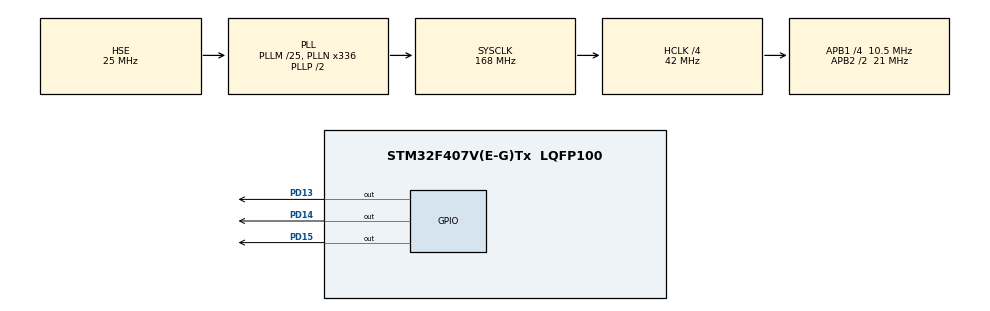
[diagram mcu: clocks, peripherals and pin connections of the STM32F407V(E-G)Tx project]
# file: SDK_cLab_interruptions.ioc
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Mcu.Family=STM32F4
RCC.PLLSourceVirtual=RCC_PLLSOURCE_HSE
PH0-OSC_IN.Signal=RCC_OSC_IN
RCC.CortexFreq_Value=42000000
NVIC.TIM6_DAC_IRQn=true\:0\:0\:false\:false\:true\:true\:true
PD15.GPIO_Speed=GPIO_SPEED_FREQ_HIGH
VP_IWDG_VS_IWDG.Mode=IWDG_Activate
TIM6.Prescaler=42000 - 1
VP_TIM6_VS_ClockSourceINT.Mode=Enable_Timer
RCC.APB1CLKDivider=RCC_HCLK_DIV4
RCC.SYSCLKSource=RCC_SYSCLKSOURCE_PLLCLK
ProjectManager.StackSize=0x400
VP_TIM7_VS_ClockSourceINT.Mode=Enable_Timer
PA13.Signal=SYS_JTMS-SWDIO
PD13.Signal=GPIO_Output
PD14.GPIO_Speed=GPIO_SPEED_FREQ_HIGH
ProjectManager.TargetToolchain=STM32CubeIDE
RCC.HCLKFreq_Value=42000000
RCC.APB2TimFreq_Value=42000000
TIM7.Period=150-1
RCC.LSE_VALUE=32768
RCC.AHBFreq_Value=42000000
PH0-OSC_IN.Mode=HSE-External-Oscillator
RCC.HSE_VALUE=25000000
PB3.Mode=JTAG_5_pins
TIM7.Prescaler=42000-1
board=custom
PD13.GPIO_Speed=GPIO_SPEED_FREQ_HIGH
RCC.VCOOutputFreq_Value=336000000
PA15.Mode=JTAG_5_pins
RCC.APB2Freq_Value=21000000
PB4.Mode=JTAG_5_pins
PA14.Mode=JTAG_5_pins
TIM6.TIM_MasterOutputTrigger=TIM_TRGO_ENABLE
PH1-OSC_OUT.Signal=RCC_OSC_OUT
RCC.AHBCLKDivider=RCC_SYSCLK_DIV4
TIM6.Period=150-1
PA13.Mode=JTAG_5_pins
Mcu.Name=STM32F407V(E-G)Tx
TIM7.TIM_MasterOutputTrigger=TIM_TRGO_ENABLE
PD14.Signal=GPIO_Output
PH1-OSC_OUT.Mode=HSE-External-Oscillator
RCC.48MHZClocksFreq_Value=84000000
PB3.Signal=SYS_JTDO-SWO
RCC.SYSCLKFreq_VALUE=168000000
Mcu.Package=LQFP100
PA14.Signal=SYS_JTCK-SWCLK
PA15.Signal=SYS_JTDI
ProjectManager.HeapSize=0x200
RCC.HSI_VALUE=16000000
NVIC.PriorityGroup=NVIC_PRIORITYGROUP_4
RCC.APB2CLKDivider=RCC_HCLK_DIV2
RCC.PLLM=25
RCC.PLLN=336
IWDG.Prescaler=IWDG_PRESCALER_64
RCC.APB1TimFreq_Value=21000000
RCC.APB1Freq_Value=10500000
PD15.Signal=GPIO_Output
NVIC.TIM7_IRQn=true\:0\:0\:false\:false\:true\:true\:true
PB4.Signal=SYS_JTRST

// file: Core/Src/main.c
/* USER CODE BEGIN Header */
/**
  ******************************************************************************
  * @file           : main.c
  * @brief          : Main program body
  ******************************************************************************
  * @attention
  *
  * <h2><center>&copy; Copyright (c) 2020 STMicroelectronics.
  * All rights reserved.</center></h2>
  *
  * This software component is licensed by ST under BSD 3-Clause license,
  * the "License"; You may not use this file except in compliance with the
  * License. You may obtain a copy of the License at:
  *                        opensource.org/licenses/BSD-3-Clause
  *
  ******************************************************************************
  */
/* USER CODE END Header */
#include "main.h"
#include "iwdg.h"
#include "tim.h"
#include "gpio.h"

/* USER CODE BEGIN Includes */
#include "trace.h"
/* USER CODE END Includes */

/* USER CODE BEGIN PV */
static const int basic_delay = 500;
static const int delay_gain = 15;

static int delay = basic_delay;

static const int frames_count = 12;
static const int leds_count = 8;

static const uint8_t frames[ 12 ][ 8 ] = {
		{ 0, 0, 0, 0, 0, 0, 1, 1 },
		{ 0, 0, 0, 0, 0, 1, 1, 0 },
		{ 0, 0, 0, 0, 1, 1, 0, 0 },
		{ 0, 0, 0, 1, 1, 0, 0, 0 },
		{ 0, 0, 1, 1, 0, 0, 0, 0 },
		{ 0, 1, 1, 0, 0, 0, 0, 0 },
		{ 1, 1, 0, 0, 0, 0, 0, 0 },
		{ 0, 1, 1, 0, 0, 0, 0, 0 },
		{ 0, 0, 1, 1, 0, 0, 0, 0 },
		{ 0, 0, 0, 1, 1, 0, 0, 0 },
		{ 0, 0, 0, 0, 1, 1, 0, 0 },
		{ 0, 0, 0, 0, 0, 1, 1, 0 }
};

static const uint8_t leds_id[] = {
		[ 0 ] = P0,
		[ 1 ] = P1,
		[ 2 ] = P2,
		[ 3 ] = P3,
		[ 4 ] = P4,
		[ 5 ] = P5,
		[ 6 ] = P6,
		[ 7 ] = P7
};
/* USER CODE END PV */

void SystemClock_Config(void);

int main(void)
{

  /* MCU Configuration--------------------------------------------------------*/

  /* Reset of all peripherals, Initializes the Flash interface and the Systick. */
  HAL_Init();

  /* Configure the system clock */
  SystemClock_Config();

  /* Initialize all configured peripherals */
  MX_GPIO_Init();
  MX_IWDG_Init();
  MX_TIM6_Init();
  MX_TIM7_Init();
  /* USER CODE BEGIN 2 */

  HAL_TIM_Base_Start_IT( &htim6 );

  /* Do not remove this code below */
  MX_TRACE_Init();
  SDK_TRACE_Start();
  /* Do not remove this code from above */

  SDK_TRACE_Timestamp(PRINT, 1);
  SDK_TRACE_Print("%s","Interruption Animation test");
  SDK_TRACE_Timestamp(PRINT, 0);
  /* Place your code from here */

  for ( int i = 0; i < frames_count; ++i ) {
	  for ( int led_counter = 0; led_counter < leds_count; ++led_counter )
		  SDK_TRACE_Timestamp( leds_id[ led_counter ], frames[ i ][ led_counter ] );
	  HAL_Delay( delay );
  }

  SDK_TRACE_Timestamp(PRINT, 1);
  SDK_TRACE_Print("%s","Test passed");
  SDK_TRACE_Timestamp(PRINT, 0);

  /* Place your code before here */
  /* Do not remove this code below */
  SDK_TRACE_Stop();
  /* Do not remove this code from above */

  /* USER CODE END 2 */

  /* Infinite loop */
  while (1)
  {

  }
}

void SystemClock_Config(void)
{
  RCC_OscInitTypeDef RCC_OscInitStruct = {0};
  RCC_ClkInitTypeDef RCC_ClkInitStruct = {0};

  /** Configure the main internal regulator output voltage
  */
  __HAL_RCC_PWR_CLK_ENABLE();
  __HAL_PWR_VOLTAGESCALING_CONFIG(PWR_REGULATOR_VOLTAGE_SCALE1);
  /** Initializes the RCC Oscillators according to the specified parameters
  * in the RCC_OscInitTypeDef structure.
  */
  RCC_OscInitStruct.OscillatorType = RCC_OSCILLATORTYPE_LSI|RCC_OSCILLATORTYPE_HSE;
  RCC_OscInitStruct.HSEState = RCC_HSE_ON;
  RCC_OscInitStruct.LSIState = RCC_LSI_ON;
  RCC_OscInitStruct.PLL.PLLState = RCC_PLL_ON;
  RCC_OscInitStruct.PLL.PLLSource = RCC_PLLSOURCE_HSE;
  RCC_OscInitStruct.PLL.PLLM = 25;
  RCC_OscInitStruct.PLL.PLLN = 336;
  RCC_OscInitStruct.PLL.PLLP = RCC_PLLP_DIV2;
  RCC_OscInitStruct.PLL.PLLQ = 4;
  if (HAL_RCC_OscConfig(&RCC_OscInitStruct) != HAL_OK)
  {
    Error_Handler();
  }
  /** Initializes the CPU, AHB and APB buses clocks
  */
  RCC_ClkInitStruct.ClockType = RCC_CLOCKTYPE_HCLK|RCC_CLOCKTYPE_SYSCLK
                              |RCC_CLOCKTYPE_PCLK1|RCC_CLOCKTYPE_PCLK2;
  RCC_ClkInitStruct.SYSCLKSource = RCC_SYSCLKSOURCE_PLLCLK;
  RCC_ClkInitStruct.AHBCLKDivider = RCC_SYSCLK_DIV4;
  RCC_ClkInitStruct.APB1CLKDivider = RCC_HCLK_DIV4;
  RCC_ClkInitStruct.APB2CLKDivider = RCC_HCLK_DIV2;

  if (HAL_RCC_ClockConfig(&RCC_ClkInitStruct, FLASH_LATENCY_1) != HAL_OK)
  {
    Error_Handler();
  }
}

/* USER CODE BEGIN 4 */
void HAL_TIM_PeriodElapsedCallback( TIM_HandleTypeDef *htim ) {
	if ( htim == &htim6 ) {
		delay += delay_gain;
	}
}
/* USER CODE END 4 */

void Error_Handler(void)
{
}

/************************ (C) COPYRIGHT STMicroelectronics *****END OF FILE****/
